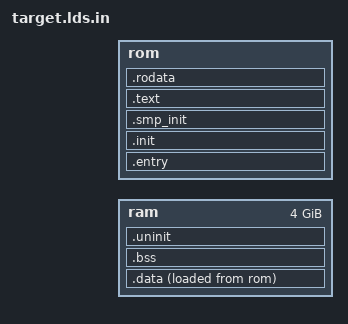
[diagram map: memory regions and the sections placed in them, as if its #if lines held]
#include "arch/memory.h"
#include "page.h"


#ifdef CONFIG_REMOVE_INIT_SECTIONS
#define	TEXT_ALIGN	ALIGN(PAGE_SIZE)
#else
#define	TEXT_ALIGN	ALIGN(__SIZEOF_LONG__)
#endif

#define	WORD_ALIGN	ALIGN(__SIZEOF_LONG__)

ENTRY(_os_startup)

MEMORY {
	ram		: ORIGIN = VIRT_ADDR + TEXT_OFFSET, LENGTH = 0xFFFFFFFF
#ifdef CONFIG_XIP
	rom		: ORIGIN = CONFIG_XIP_VADDR, LENGTH = CONFIG_XIP_SIZE
#else
#define	rom ram
#endif
}

SECTIONS
{

	.entry :  {
		KEEP(*(.entry))
			*(.entry.text)
	} > rom

	.init : {
			*(.startup.text)
			*(.init.text)

#ifdef CONFIG_INITCALL
		. = WORD_ALIGN;
		PROVIDE(__INITCALL_LIST__ = .);
			KEEP(*(SORT(.initcall*)))
			LONG(0);
#endif
	} > rom

#ifdef CONFIG_SMP
	.smp_init : WORD_ALIGN {
		__SMP_INITCALL_LIST__ = .;
			KEEP(*(SORT(.smp_initcall*)))
			LONG(0);
	} > rom
#endif

	.text : TEXT_ALIGN {
			*(.vectors)
			*(.text*)
	} > rom

	.rodata : {
			*(SORT_BY_ALIGNMENT(.rodata*))
	} > rom

	.data : WORD_ALIGN {
		PROVIDE(__data_load = LOADADDR(.data));
		PROVIDE(__data_start = .);
			*(SORT_BY_ALIGNMENT(.data*))
		. = WORD_ALIGN;
		PROVIDE(__data_end = .);
	} > ram AT> rom

	.bss : WORD_ALIGN {
		PROVIDE(__bss_start = .);
			*(
				SORT_BY_ALIGNMENT(.bss*)
				SORT_BY_ALIGNMENT(COMMON)
			)
		PROVIDE(__bss_end = .);
	} > ram

	.uninit (NOLOAD) : TEXT_ALIGN {
			*(SORT_BY_ALIGNMENT(.uninit*))
	} > ram

	. = ALIGN(PAGE_SIZE);
	PROVIDE(pagemap = .);
}
